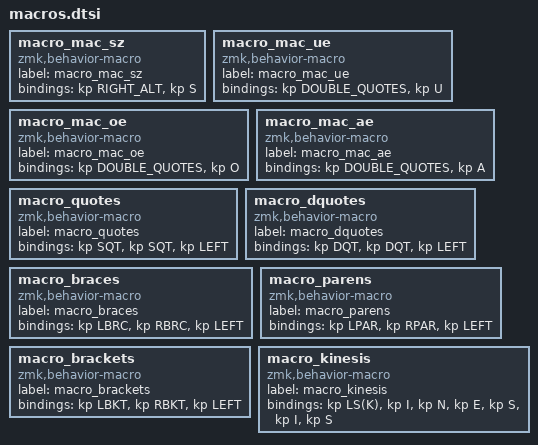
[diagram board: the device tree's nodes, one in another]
macro_mac_sz: macro_mac_sz{
compatible = "zmk,behavior-macro";
label = "macro_mac_sz";
#binding-cells = <0>;
bindings = <&kp RIGHT_ALT>, <&kp S>;
};
macro_mac_ue: macro_mac_ue{
compatible = "zmk,behavior-macro";
label = "macro_mac_ue";
#binding-cells = <0>;
bindings = <&kp DOUBLE_QUOTES>, <&kp U>;
};
macro_mac_oe: macro_mac_oe{
compatible = "zmk,behavior-macro";
label = "macro_mac_oe";
#binding-cells = <0>;
bindings = <&kp DOUBLE_QUOTES>, <&kp O>;
};
macro_mac_ae: macro_mac_ae{
compatible = "zmk,behavior-macro";
label = "macro_mac_ae";
#binding-cells = <0>;
bindings = <&kp DOUBLE_QUOTES>, <&kp A>;
};
macro_quotes: macro_quotes{
compatible = "zmk,behavior-macro";
label = "macro_quotes";
#binding-cells = <0>;
bindings = <&kp SQT>, <&kp SQT>, <&kp LEFT>;
};
macro_dquotes: macro_dquotes{
compatible = "zmk,behavior-macro";
label = "macro_dquotes";
#binding-cells = <0>;
bindings = <&kp DQT>, <&kp DQT>, <&kp LEFT>;
};
macro_braces: macro_braces{
compatible = "zmk,behavior-macro";
label = "macro_braces";
#binding-cells = <0>;
bindings = <&kp LBRC>, <&kp RBRC>, <&kp LEFT>;
};
macro_parens: macro_parens{
compatible = "zmk,behavior-macro";
label = "macro_parens";
#binding-cells = <0>;
bindings = <&kp LPAR>, <&kp RPAR>, <&kp LEFT>;
};
macro_brackets: macro_brackets{
compatible = "zmk,behavior-macro";
label = "macro_brackets";
#binding-cells = <0>;
bindings = <&kp LBKT>, <&kp RBKT>, <&kp LEFT>;
};
macro_kinesis: macro_kinesis{
compatible = "zmk,behavior-macro";
label = "macro_kinesis";
#binding-cells = <0>;
bindings = <&kp LS(K)>, <&kp I>, <&kp N>, <&kp E>, <&kp S>, <&kp I>, <&kp S>;
};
